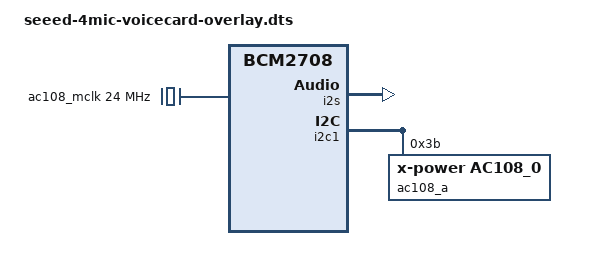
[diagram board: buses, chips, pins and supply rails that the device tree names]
/dts-v1/;
/plugin/;

/ {
    compatible = "brcm,bcm2708";
	fragment@0 {
		target = <&i2s>;
		__overlay__ {
			#sound-dai-cells = <0>;
			status = "okay";
        	};
	};
    fragment@1 {
        target-path = "/clocks";
        __overlay__ {
            ac108_mclk: codec-mclk {
                compatible = "fixed-clock";
                #clock-cells = <0>;
                clock-frequency = <24000000>;
            };  
        };
    };
    fragment@2 {
		target = <&i2c1>;
		__overlay__ {
			#address-cells = <1>;
			#size-cells = <0>;
			status = "okay";

			ac108_a: ac108@3b{
				compatible = "x-power,ac108_0";
				reg = <0x3b>;
				#sound-dai-cells = <0>;
                data-protocol = <1>;
			};
		};
    };



    fragment@3 {
        target = <&sound>;
        sound_overlay: __overlay__ {
                compatible = "simple-audio-card";
                simple-audio-card,format = "i2s";
                simple-audio-card,name = "seeed-4mic-voicecard"; 
                status = "okay";
                
                simple-audio-card,bitclock-master = <&dailink0_slave>;
                simple-audio-card,frame-slave = <&dailink0_slave>;               
                dailink0_slave: simple-audio-card,cpu {
                    sound-dai = <&i2s>;
                };
                codec_dai: simple-audio-card,codec {
                    sound-dai = <&ac108_a>;
                    clocks =  <&ac108_mclk>;
                };
        };
    };
    __overrides__ {
        card-name = <&sound_overlay>,"seeed-voicecard,name";
    };    

    
};

